# GPMC register map
Vendor: Texas Instruments
Peripheral module from a debugger description file (folder omap4430).
Registers are 32-bit, read-write, reset 0x0 unless marked. A register's access mark holds for its fields unless they carry their own. Offsets are as the file gives them; lines under a group give offsets from that group; [hi:lo] are bit positions; {n}, {i} and the like mark numbered series; 'fields as' and 'values as' point back to an identical list; <NAME> marks a mode.

## GPMC
0x00 GPMC_REVISION ro reset not defined — This register contains the IP revision code.
  [31:0] REVISION — IP revision
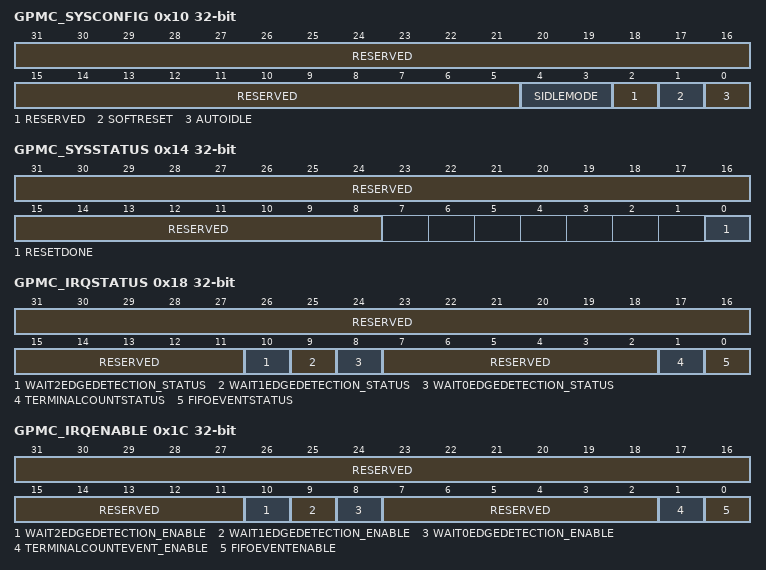
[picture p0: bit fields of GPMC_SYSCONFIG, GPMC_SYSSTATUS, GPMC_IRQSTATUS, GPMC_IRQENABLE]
0x10 GPMC_SYSCONFIG — This register controls the various parameters of the Interconnect.
  [31:5] RESERVED — Write 0s for future compatibility. Reads return 0s.
  [4:3] SIDLEMODE — 0x0: Force-idle. An idle request is acknowledged unconditionally
    1=No-idle. An idle request is never acknowledged; 2=Smart-idle. Acknowledgment to an idle request is given based on the internal activity of the module; 3=Do not use
  [2] RESERVED — Write 0 for future compatibility Reads returns 0
  [1] SOFTRESET — Software reset. Set this bit to 1 triggers a module reset. This bit is automatically reset by hardware. During reads, it always returns 0.
    0=Normal mode; 1=The module is reset
  [0] AUTOIDLE — Internal Interface clock gating strategy
    0=Interface clock is free-running; 1=Automatic Interface clock gating strategy is applied, based on the Interconnect activity
0x14 GPMC_SYSSTATUS ro (reset mask 0xFFFFFFFE) — This register provides status information about the module, excluding the interrupt status information
  [31:8] RESERVED — Reads returns 0
  [0] RESETDONE — Internal reset monitoring
    0=Internal module reset in ongoing; 1=Reset completed
0x18 GPMC_IRQSTATUS — This interrupt status register regroups all the status of the module internal events that can generate an interrupt.
  [31:11] RESERVED — Write 0s for future compatibility. Read returns 0s.
  [10] WAIT2EDGEDETECTION_STATUS — Status of the Wait2 Edge Detection interrupt
    0=WAIT2EDGEDETECTION_STATUS_0_r (A transition on WAIT2 input pin has not been detected); 0=WAIT2EDGEDETECTION_STATUS_0_w (WAIT2EDGEDETECTIONSTATUS bit unchanged); 1=WAIT2EDGEDETECTION_STATUS_1_r (A transition on WAIT2 input pin has been detected); 1=WAIT2EDGEDETECTION_STATUS_1_w (WAIT2EDGEDETECTIONSTATUS bit is reset)
  [9] WAIT1EDGEDETECTION_STATUS — Status of the Wait1 Edge Detection interrupt
    0=WAIT1EDGEDETECTION_STATUS_0_r (A transition on WAIT1 input pin has not been detected); 0=WAIT1EDGEDETECTION_STATUS_0_w (WAIT1EDGEDETECTIONSTATUS bit unchanged); 1=WAIT1EDGEDETECTION_STATUS_1_r (A transition on WAIT1 input pin has been detected); 1=WAIT1EDGEDETECTION_STATUS_1_w (WAIT1EDGEDETECTIONSTATUS bit is reset)
  [8] WAIT0EDGEDETECTION_STATUS — Status of the Wait0 Edge Detection interrupt
    0=WAIT0EDGEDETECTION_STATUS_0_r (A transition on WAIT0 input pin has not been detected); 0=WAIT0EDGEDETECTION_STATUS_0_w (WAIT0EDGEDETECTIONSTATUS bit unchanged); 1=WAIT0EDGEDETECTION_STATUS_1_r (A transition on WAIT0 input pin has been detected); 1=WAIT0EDGEDETECTION_STATUS_1_w (WAIT0EDGEDETECTIONSTATUS bit is reset)
  [7:2] RESERVED — Write 0s for future compatibility. Read returns 0s.
  [1] TERMINALCOUNTSTATUS — Status of the TerminalCountEvent interrupt
    0=TERMINALCOUNTSTATUS_0_r (Indicates that CountValue is greater than 0); 0=TERMINALCOUNTSTATUS_0_w (TERMINALCOUNTSTATUS bit unchanged); 1=TERMINALCOUNTSTATUS_1_r (Indicates that CountValue is equal to 0); 1=TERMINALCOUNTSTATUS_1_w (TERMINALCOUNTSTATUS bit is reset)
  [0] FIFOEVENTSTATUS — Status of the FIFOEvent interrupt
    0=FIFOEVENTSTATUS_0_r (Indicates than less than[16] FIFOTHRESHOLDSTATUS bytes are available in prefetch mode and less than FIFOTHRESHOLD bytes free places are available in write-posting mode.); 0=FIFOEVENTSTATUS_0_w (FIFOEVENTSTATUS bit unchanged); 1=FIFOEVENTSTATUS_1_r (Indicates than at least[16] FIFOTHRESHOLDSTATUS bytes are available in prefetch mode and at least FIFOTHRESHOLD bytes free places are available in write-posting mode.); 1=FIFOEVENTSTATUS_1_w (FIFOEVENTSTATUS bit is reset)
0x1C GPMC_IRQENABLE — The interrupt enable register allows to mask/unmask the module internal sources of interrupt, on a event-by-event basis.
  [31:11] RESERVED — Write 0s for future compatibility. Read returns 0s.
  [10] WAIT2EDGEDETECTION_ENABLE — Enables the Wait2 Edge Detection interrupt
    0=Wait2EdgeDetection interrupt is masked; 1=Wait2EdgeDetection event generates an interrupt if occurs
  [9] WAIT1EDGEDETECTION_ENABLE — Enables the Wait1 Edge Detection interrupt
    0=Wait1EdgeDetection interrupt is masked; 1=Wait1EdgeDetection event generates an interrupt if occurs
  [8] WAIT0EDGEDETECTION_ENABLE — Enables the Wait0 Edge Detection interrupt
    0=Wait0EdgeDetection interrupt is masked; 1=Wait0EdgeDetection event generates an interrupt if occurs
  [7:2] RESERVED — Write 0s for future compatibility. Read returns 0s.
  [1] TERMINALCOUNTEVENT_ENABLE — Enables TerminalCountEvent interrupt issuing in prefetch or write-posting mode
    0=TerminalCountEvent interrupt is masked; 1=TerminalCountEvent interrupt is not masked
  [0] FIFOEVENTENABLE — Enables the FIFOEvent interrupt
    0=FIFOEvent interrupt is masked; 1=FIFOEvent interrupt is not masked
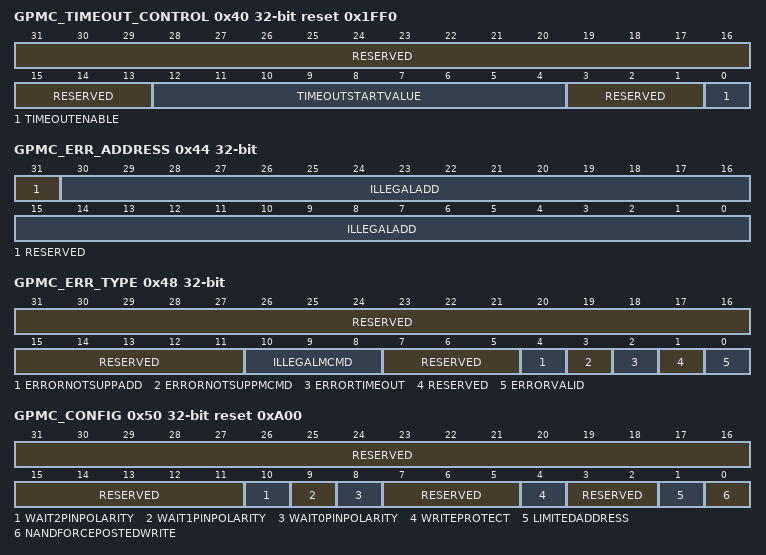
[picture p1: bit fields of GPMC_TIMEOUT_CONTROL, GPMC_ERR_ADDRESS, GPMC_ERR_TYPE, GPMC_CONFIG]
0x40 GPMC_TIMEOUT_CONTROL reset 0x1FF0 — The register allows the user to set the start value of the timeout counter
  [31:13] RESERVED — Write 0s for future compatibility. Read returns 0s.
  [12:4] TIMEOUTSTARTVALUE — Start value of the time-out counter 0x000: Zero GPMC_FCLK cycle 0x001: One GPMC_FCLK cycle ... 0x1FF: 511 GPMC_FCLK cycles
  [3:1] RESERVED — Write 0s for future compatibility. Read returns 0s.
  [0] TIMEOUTENABLE — Enable bit of the TimeOut feature
    0=TimeOut feature is disabled; 1=TimeOut feature is enabled
0x44 GPMC_ERR_ADDRESS access per field — The register stores the address of the illegal access when an error occurs
  [31] RESERVED rw — Write 0s for future compatibility. Read returns 0.
  [30:0] ILLEGALADD ro — Address of illegal access A30: 0 for memory region, 1 for GPMC register region A29-A0: 1 GBytes max
0x48 GPMC_ERR_TYPE access per field — The register stores the type of error when an error occurs
  [31:11] RESERVED rw — Write 0s for future compatibility. Read returns 0s.
  [10:8] ILLEGALMCMD ro — System Command of the transaction that caused the error
  [7:5] RESERVED rw — Write 0s for future compatibility. Read returns 0s.
  [4] ERRORNOTSUPPADD ro — Not supported Address error
    0=No error occurs; 1=The error is due to a non supported Address
  [3] ERRORNOTSUPPMCMD ro — Not supported Command error
    0=No error occurs; 1=The error is due to a non supported Command
  [2] ERRORTIMEOUT ro — Time-out error
    0=No error occurs; 1=The error is due to a time out
  [1] RESERVED rw — Write 0s for future compatibility. Read returns 0.
  [0] ERRORVALID rw — Error validity status - Must be explicitly cleared with a write 1 transaction
    0=All error fields no longer valid; 1=Error detected and logged in the other error fields
0x50 GPMC_CONFIG reset 0xA00 — The configuration register allows global configuration of the GPMC
  [31:11] RESERVED — Write 0s for future compatibility. Read returns 0s.
  [10] WAIT2PINPOLARITY — Selects the polarity of input pin WAIT2
    0=WAIT2 active low; 1=WAIT2 active high
  [9] WAIT1PINPOLARITY — Selects the polarity of input pin WAIT1
    0=WAIT1 active low; 1=WAIT1 active high
  [8] WAIT0PINPOLARITY — Selects the polarity of input pin WAIT0
    0=WAIT0 active low; 1=WAIT0 active high
  [7:5] RESERVED — Write 0s for future compatibility. Read returns 0s.
  [4] WRITEPROTECT — Controls the WP output pin level
    0=WP output pin is low; 1=WP output pin is high
  [3:2] RESERVED — Write 0s for future compatibility. Read returns 0s.
  [1] LIMITEDADDRESS — Limited Address device support
    0=No effect; 1=A26-A11 are not modified during an external memory access
  [0] NANDFORCEPOSTEDWRITE — Enables the Force Posted Write feature to NAND Cmd/Add/Data location
    0=Disables Force Posted Write; 1=Enables Force Posted Write
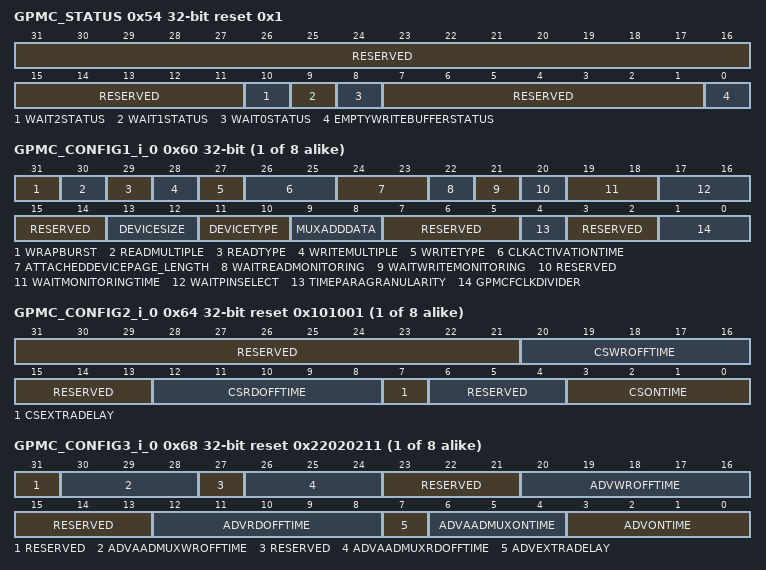
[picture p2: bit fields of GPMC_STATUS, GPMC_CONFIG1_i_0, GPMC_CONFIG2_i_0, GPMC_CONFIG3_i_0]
0x54 GPMC_STATUS access per field reset 0x1 (reset mask 0xFFFFF8FF) — The status register provides global status bits of the GPMC
  [31:11] RESERVED rw — Write 0s for future compatibility. Read returns 0s.
  [10] WAIT2STATUS ro — Is a copy of input pin WAIT2. (Reset value is WAIT2 input pin sampled at IC reset)
    0=WAIT2 asserted (inactive state); 1=WAIT2 deasserted
  [9] WAIT1STATUS ro — Is a copy of input pin WAIT1. (Reset value is WAIT1 input pin sampled at IC reset)
    0=WAIT1 asserted (inactive state); 1=WAIT1 deasserted
  [8] WAIT0STATUS ro — Is a copy of input pin WAIT0. (Reset value is WAIT0 input pin sampled at IC reset)
    0=WAIT0 asserted (inactive state); 1=WAIT0 deasserted
  [7:1] RESERVED rw — Write 0s for future compatibility. Reads returns 0
  [0] EMPTYWRITEBUFFERSTATUS ro — Stores the empty status of the write buffer
    0=Write Buffer is not empty; 1=Write Buffer is empty
{0x60+0x30*i} GPMC_CONFIG1_i_{i} (reset mask 0xFFBCCCFF) (i=0..7) — The configuration register 1 sets signal control parameters per chip-select
  [31] WRAPBURST — Enables the wrapping burst capability. Must be set if the attached device is configured in wrapping burst
    0=Synchronous wrapping burst not supported; 1=Synchronous wrapping burst supported
  [30] READMULTIPLE — Selects the read single or multiple access
    0=Single access; 1=Multiple access (burst if synchronous, page if asynchronous)
  [29] READTYPE — Selects the read mode operation
    0=Read Asynchronous; 1=Read Synchronous
  [28] WRITEMULTIPLE — Selects the write single or multiple access
    0=Single access; 1=Multiple access (burst if synchronous, considered as single if asynchronous)
  [27] WRITETYPE — Selects the write mode operation
    0=Write Asynchronous; 1=Write Synchronous
  [26:25] CLKACTIVATIONTIME — Output GPMC_CLK activation time
    0=First rising edge of GPMC_CLK at start access time; 1=First rising edge of GPMC_CLK one GPMC_FCLK cycle after start access time; 2=First rising edge of GPMC_CLK two GPMC_FCLK cycles after start access time
  [24:23] ATTACHEDDEVICEPAGE_LENGTH — Specifies the attached device page (burst) length
    0=4 Words; 1=8 Words; 2=16 Words
  [22] WAITREADMONITORING — Selects the Wait monitoring configuration for Read accesses (Reset value is input pin sampled at IC reset)
    0=Wait pin is not monitored for read accesses; 1=Wait pin is monitored for read accesses
  [21] WAITWRITEMONITORING — Selects the Wait monitoring configuration for Write accesses
    0=Wait pin is not monitored for write accesses; 1=Wait pin is monitored for write accesses
  [20] RESERVED — Write 0s for future compatibility. Read returns 0.
  [19:18] WAITMONITORINGTIME — Selects input pin Wait monitoring time
    0=Wait pin is monitored with valid data; 1=Wait pin is monitored one GPMC_CLK cycle before valid data; 2=Wait pin is monitored two GPMC_CLK cycle before valid data
  [17:16] WAITPINSELECT — Selects the input WAIT pin for this chip-select (Reset value is input pin sampled at IC reset for CS0 and 0 for CS1-7)
    0=Wait input pin is WAIT0; 1=Wait input pin is WAIT1; 2=Wait input pin is WAIT2
  [15:14] RESERVED — Write 0s for future compatibility. Reads returns 0
  [13:12] DEVICESIZE — Selects the device size attached (Reset value is input pin sampled at IC reset for CS0 and 0x1 for CS1 to CS7)
    0=8 bit; 1=16 bit
  [11:10] DEVICETYPE — Selects the attached device type
    0=NOR Flash like, asynchronous and synchronous devices; 2=NAND Flash like devices, stream mode
  [9:8] MUXADDDATA — Enables the address and data multiplexed protocol (Reset value is input pin sampled at IC reset for CS0 and 0 for CS1-CS7)
    0=Non-multiplexed attached device; 1=AAD-mux protocol device; 2=Address and data multiplexed attached device
  [7:5] RESERVED — Write 0s for future compatibility. Read returns 0s.
  [4] TIMEPARAGRANULARITY — Signals timing latencies scalar factor (RD/WRCYCLETIME, RD/WRACCESSTIME, PAGEBURSTACCESSTIME, CSONTIME, CSRD/WROFFTIME, ADVONTIME, ADVRD/WROFFTIME, OEONTIME, OEOFFTIME, WEONTIME, WEOFFTIME, CYCLE2CYCLEDELAY, BUSTURNAROUND, TIMEOUTSTARTVALUE, WRDATAONADMUXBUS)
    0=x1 latencies; 1=x2 latencies
  [3:2] RESERVED — Write 0s for future compatibility. Read returns 0s.
  [1:0] GPMCFCLKDIVIDER — Divides the GPMC_FCLK clock
    0=GPMC_CLK frequency = GPMC_FCLK frequency; 1=GPMC_CLK frequency = GPMC_FCLK frequency / 2; 2=GPMC_CLK frequency = GPMC_FCLK frequency / 3; 3=GPMC_CLK frequency = GPMC_FCLK frequency /4
{0x64+0x30*i} GPMC_CONFIG2_i_{i} reset 0x101001 (i=0..7) — CS signal timing parameter configuration
  [31:21] RESERVED — Write 0s for future compatibility. Reads returns 0
  [20:16] CSWROFFTIME — CS i de-assertion time from start cycle time for write accesses 0x00: 0 GPMC_FCLK cycle 0x01: 1 GPMC_FCLK cycle ... 0x1F: 31 GPMC_FCLK cycles
  [15:13] RESERVED — Write 0s for future compatibility. Read returns 0s.
  [12:8] CSRDOFFTIME — CS i de-assertion time from start cycle time for read accesses 0x00: 0 GPMC_FCLK cycle 0x01: 1 GPMC_FCLK cycle ... 0x1F: 31 GPMC_FCLK cycles
  [7] CSEXTRADELAY — CS i Add Extra Half GPMC_FCLK cycle
    0=CS i Timing control signal is not delayed; 1=CS i Timing control signal is delayed of half GPMC_FCLK clock cycle
  [6:4] RESERVED — Write 0s for future compatibility. Read returns 0s.
  [3:0] CSONTIME — CS i assertion time from start cycle time 0x0: 0 GPMC_FCLK cycle 0x1: 1 GPMC_FCLK cycle ... 0xF: 15 GPMC_FCLK cycles
{0x68+0x30*i} GPMC_CONFIG3_i_{i} reset 0x22020211 (i=0..7) — nADV signal timing parameter configuration
  [31] RESERVED — Write 0s for future compatibility. Read returns 0s.
  [30:28] ADVAADMUXWROFFTIME — nADV de-assertion for first address phase when using the AAD-mux protocol 0x0: 0 GPMC_FCLK cycle 0x1: 1 GPMC_FCLK cycle ... 0x7: 7 GPMC_FCLK cycles
  [27] RESERVED — Write 0s for future compatibility. Read returns 0s.
  [26:24] ADVAADMUXRDOFFTIME — nADV assertion for first address phase when using the AAD-mux protocol 0x0: 0 GPMC_FCLK cycle 0x1: 1 GPMC_FCLK cycle ... 0x7: 7 GPMC_FCLK cycles
  [23:21] RESERVED — Write 0s for future compatibility. Read returns 0s.
  [20:16] ADVWROFFTIME — nADV de-assertion time from start cycle time for write accesses 0x00: 0 GPMC_FCLK cycle 0x01: 1 GPMC_FCLK cycle ... 0x1F: 31 GPMC_FCLK cycles
  [15:13] RESERVED — Write 0s for future compatibility. Read returns 0s.
  [12:8] ADVRDOFFTIME — nADV de-assertion time from start cycle time for read accesses 0x00: 0 GPMC_FCLK cycle 0x01: 1 GPMC_FCLK cycle ... 0x1F: 31 GPMC_FCLK cycles
  [7] ADVEXTRADELAY — nADV Add Extra Half GPMC_FCLK cycle
    0=nADV Timing control signal is not delayed; 1=nADV Timing control signal is delayed of half GPMC_FCLK clock cycle
  [6:4] ADVAADMUXONTIME — nADV assertion for first address phase when using the AAD-mux protocol 0x0: 0 GPMC_FCLK cycle 0x1: 1 GPMC_FCLK cycle ... 0x7: 7 GPMC_FCLK cycles
  [3:0] ADVONTIME — nADV assertion time from start cycle time 0x0: 0 GPMC_FCLK cycle 0x1: 1 GPMC_FCLK cycle ... 0xF: 15 GPMC_FCLK cycles
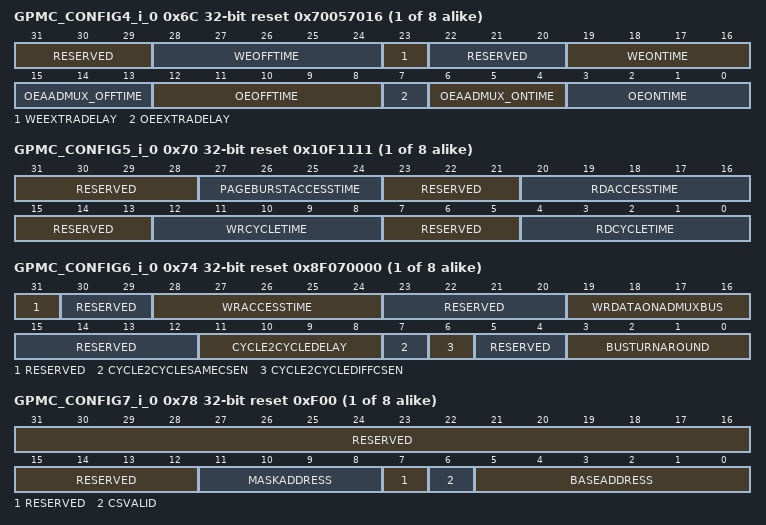
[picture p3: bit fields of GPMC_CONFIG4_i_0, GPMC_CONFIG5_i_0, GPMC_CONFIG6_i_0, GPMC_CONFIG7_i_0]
{0x6C+0x30*i} GPMC_CONFIG4_i_{i} reset 0x70057016 (i=0..7) — nWE and nOE signals timing parameter configuration
  [31:29] RESERVED — Write 0s for future compatibility. Read returns 0s.
  [28:24] WEOFFTIME — nWE de-assertion time from start cycle time 0x00: 0 GPMC_FCLK cycle 0x01: 1 GPMC_FCLK cycle ... 0x1F: 31 GPMC_FCLK cycles
  [23] WEEXTRADELAY — nWE Add Extra Half GPMC_FCLK cycle
    0=nWE Timing control signal is not delayed; 1=nWE Timing control signal is delayed of half GPMC_FCLK clock cycle
  [22:20] RESERVED — Write 0s for future compatibility. Read returns 0s.
  [19:16] WEONTIME — nWE assertion time from start cycle time 0x0: 0 GPMC_FCLK cycle 0x1: 1 GPMC_FCLK cycle ... 0xF: 15 GPMC_FCLK cycles
  [15:13] OEAADMUX_OFFTIME — nOE de-assertion time for the first address phase in an AAD-mux access 0x0: 0 GPMC_FCLK cycle 0x1: 1 GPMC_FCLK cycle ... 0x7: 7 GPMC_FCLK cycles
  [12:8] OEOFFTIME — nOE de-assertion time from start cycle time 0x00: 0 GPMC_FCLK cycle 0x01: 1 GPMC_FCLK cycle ... 0x1F: 31 GPMC_FCLK cycles
  [7] OEEXTRADELAY — nOE Add Extra Half GPMC_FCLK cycle
    0=nOE Timing control signal is not delayed; 1=nOE Timing control signal is delayed of half GPMC_FCLK clock cycle
  [6:4] OEAADMUX_ONTIME — nOE assertion time for the first address phase in an AAD-mux access 0x0: 0 GPMC_FCLK cycle 0x1: 1 GPMC_FCLK cycle ... 0x7: 7 GPMC_FCLK cycles
  [3:0] OEONTIME — nOE assertion time from start cycle time 0x0: 0 GPMC_FCLK cycle 0x1: 1 GPMC_FCLK cycle ... 0xF: 15 GPMC_FCLK cycles
{0x70+0x30*i} GPMC_CONFIG5_i_{i} reset 0x10F1111 (i=0..7) — RdAccessTime and CycleTime timing parameters configuration
  [31:28] RESERVED — Write 0s for future compatibility. Read returns 0s.
  [27:24] PAGEBURSTACCESSTIME — Delay between successive words in a multiple access 0x0: 0 GPMC_FCLK cycle 0x1: 1 GPMC_FCLK cycle ... 0xF: 15 GPMC_FCLK cycles
  [23:21] RESERVED — Write 0s for future compatibility. Read returns 0s.
  [20:16] RDACCESSTIME — Delay between start cycle time and first data valid 0x00: 0 GPMC_FCLK cycle 0x01: 1 GPMC_FCLK cycle ... 0x1F: 31 GPMC_FCLK cycles
  [15:13] RESERVED — Write 0s for future compatibility. Reads returns 0
  [12:8] WRCYCLETIME — Total write cycle time 0x00: 0 GPMC_FCLK cycle 0x01: 1 GPMC_FCLK cycle ... 0x1F: 31 GPMC_FCLK cycles
  [7:5] RESERVED — Write 0s for future compatibility. Read returns 0s.
  [4:0] RDCYCLETIME — Total read cycle time 0x00: 0 GPMC_FCLK cycle 0x01: 1 GPMC_FCLK cycle ... 0x1F: 31 GPMC_FCLK cycles
{0x74+0x30*i} GPMC_CONFIG6_i_{i} reset 0x8F070000 (i=0..7) — WrAccessTime, WrDataOnADmuxBus, Cycle2Cycle and BusTurnAround parameters configuration
  [31] RESERVED — TI Internal use - Do not modify.
  [30:29] RESERVED — Write 0s for future compatibility. Read returns 0s.
  [28:24] WRACCESSTIME — Delay from start access time to the GPMC_FCLK rising edge corresponding the the GPMC_CLK rising edge used by the attached memory for the first data capture 0x00: 0 GPMC_FCLK cycle 0x01: 1 GPMC_FCLK cycle ... 0x1F: 31 GPMC_FCLK cycles
  [23:20] RESERVED — Write 0s for future compatibility. Read returns 0s.
  [19:16] WRDATAONADMUXBUS — Specifies on which GPMC_FCLK rising edge the first data of the synchronous burst write is driven in the add/data mux bus
  [15:12] RESERVED — Write 0s for future compatibility. Read returns 0s.
  [11:8] CYCLE2CYCLEDELAY — Chip-select high pulse delay between successive accesses 0x0: 0 GPMC_FCLK cycle 0x1: 1 GPMC_FCLK cycle ... 0xF: 15 GPMC_FCLK cycles
  [7] CYCLE2CYCLESAMECSEN — Add CYCLE2CYCLEDELAY between successive accesses to the same CS (any access type)
    0=No delay between the two accesses; 1=Add CYCLE2CYCLEDELAY
  [6] CYCLE2CYCLEDIFFCSEN — Add CYCLE2CYCLEDELAY between successive accesses to a different CS (any access type)
    0=No delay between the two accesses; 1=Add CYCLE2CYCLEDELAY
  [5:4] RESERVED — Write 0s for future compatibility. Reads returns 0
  [3:0] BUSTURNAROUND — Bus turn around latency between successive accesses to the same CS (read to write) or to a different CS (read to read and read to write) 0x0: 0 GPMC_FCLK cycle 0x1: 1 GPMC_FCLK cycle ... 0xF: 15 GPMC_FCLK cycles
{0x78+0x30*i} GPMC_CONFIG7_i_{i} reset 0xF00 (reset mask 0xFFFFFFBF) (i=0..7) — CS address mapping configuration
  [31:12] RESERVED — Write 0s for future compatibility. Read returns 0s.
  [11:8] MASKADDRESS — CS mask address. 0x1000: Chip-select size of 128 Mbytes 0x1100: Chip-select size of 64 Mbytes 0x1110: Chip-select size of 32 Mbytes 0x1111: Chip-select size of 16 Mbytes Other values must be avoided as they create holes in the chip-select address space.
  [7] RESERVED — Write 0s for future compatibility. Read returns 0.
  [6] CSVALID — CS enable
    0=CS disabled; 1=CS enabled
  [5:0] BASEADDRESS — CSi base address where i = 0 to 7 (16M bytes minimum granularity) bits [5:0] corresponds to A29, A28, A27, A26, A25, and A24. See
{0x7C+0x30*i} GPMC_NAND_COMMAND_i_{i} wo reset not defined (i=0..7) — This register is not a true register, just an address location.
  [31:0] GPMC_NAND_COMMAND — This register is not a true register, just an address location. Writing data at theGPMC_NAND_COMMAND_i location places the data as the NAND command value on the bus, using a regular asynchronous write access.
{0x80+0x30*i} GPMC_NAND_ADDRESS_i_{i} wo reset not defined (i=0..7) — This register is not a true register, just an address location.
  [31:0] GPMC_NAND_ADDRESS — This register is not a true register, just an address location. Writing data at theGPMC_NAND_ADDRESS_i location places the data as the NAND partial address value on the bus, using a regular asynchronous write access.
{0x84+0x30*i} GPMC_NAND_DATA_i_{i} wo reset not defined (i=0..7) — This register is not a true register, just an address location.
  [31:0] GPMC_NAND_DATA — This register is not a true register, just an address location. Reading data from theGPMC_NAND_DATA_i location or from any location in the associated chip-select memory region activates an asynchronous read access.
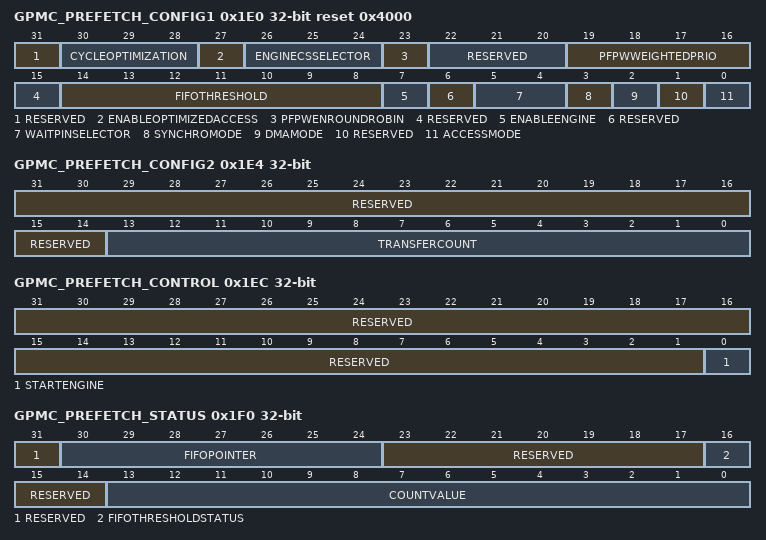
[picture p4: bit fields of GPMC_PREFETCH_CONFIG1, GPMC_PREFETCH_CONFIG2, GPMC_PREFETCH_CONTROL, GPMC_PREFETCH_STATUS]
0x1E0 GPMC_PREFETCH_CONFIG1 reset 0x4000 — Prefetch engine configuration 1
  [31] RESERVED — Write 0s for future compatibility. Read returns 0.
  [30:28] CYCLEOPTIMIZATION — Define the number of GPMC_FCLK cycles to be subtracted from RDCYCLETIME, WRCYCLETIME, ACCESSTIME, CSRDOFFTIME, CSWROFFTIME, ADVRDOFFTIME, ADVWROFFTIME, OEOFFTIME, WEOFFTIME 0x0: 0 GPMC_FCLK cycle 0x1: 1 GPMC_FCLK cycle ... 0x7: 7 GPMC_FCLK cycles
  [27] ENABLEOPTIMIZEDACCESS — Enables access cycle optimization
    0=Access cycle optimization is disabled; 1=Access cycle optimization is enabled
  [26:24] ENGINECSSELECTOR — Selects the CS where Prefetch Postwrite engine is active 0x0: CS0 0x1: CS1 0x2: CS2 0x3: CS3 0x4: CS4 0x5: CS5 0x6: CS6 0x7: CS7
  [23] PFPWENROUNDROBIN — Enables the PFPW RoundRobin arbitration
    0=Prefetch Postwrite engine round robin arbitration is disabled; 1=Prefetch Postwrite engine round robin arbitration is enabled
  [22:20] RESERVED — Write 0s for future compatibility. Read returns 0s.
  [19:16] PFPWWEIGHTEDPRIO — When an arbitration occurs between a DMA and a PFPW engine access, the DMA is always serviced. If the PFPWEnRoundRobin is enabled, 0x0: the next access is granted to the PFPW engine, 0x1: the two next accesses are granted to the PFPW engine, ..., 0xF: the 16 next accesses are granted to the PFPW engine.
  [15] RESERVED — Write 0s for future compatibility. Read returns 0.
  [14:8] FIFOTHRESHOLD — Selects the maximum number of bytes read from the FIFO or written to the FIFO by the host on a DMA or interrupt request 0x00: 0 byte 0x01: 1 byte ... 0x40: 64 bytes
  [7] ENABLEENGINE — Enables the Prefetch Postwite engine
    0=Prefetch Postwrite engine is disabled; 1=Prefetch Postwrite engine is enabled
  [6] RESERVED — Write 0s for future compatibility. Read returns 0.
  [5:4] WAITPINSELECTOR — Select which wait pin edge detector should start the engine in synchronized mode
    0=Selects Wait0 EdgeDetection; 1=Selects Wait1 EdgeDetection; 2=Selects Wait2 EdgeDetection
  [3] SYNCHROMODE — Selects when the engine starts the access to CS
    0=Engine starts the access to CS as soon as STARTENGINE is set; 1=Engine starts the access to CS as soon as STARTENGINE is set AND wait to non wait edge detection on the selected wait pin
  [2] DMAMODE — Selects interrupt synchronization or DMA request synchronization
    0=Interrupt synchronization is enabled. Only interrupt line will be activated on FIFO threshold crossing.; 1=DMA request synchronization is enabled. A DMA request protocol is used.
  [1] RESERVED — Write 0s for future compatibility. Read returns 0.
  [0] ACCESSMODE — Selects prefetch read or write-posting accesses
    0=Prefetch read mode; 1=Write-posting mode
0x1E4 GPMC_PREFETCH_CONFIG2 — Prefetch engine configuration 2
  [31:14] RESERVED — Write 0s for future compatibility. Read returns 0s.
  [13:0] TRANSFERCOUNT — Selects the number of bytes to be read or written by the engine to the selected CS 0x0000: 0 byte 0x0001: 1 byte ... 0x2000: 8 Kbytes
0x1EC GPMC_PREFETCH_CONTROL — Prefetch engine control
  [31:1] RESERVED — Write 0s for future compatibility. Read returns 0s.
  [0] STARTENGINE — Resets the FIFO pointer and starts the engineWrite 0x0 stops the engine . Write 0x1 resets the FIFO pointer to 0x0 in prefetch mode and 0x40 in postwrite mode and starts the engine .
    0=STARTENGINE_0_r (Engine is stopped); 1=STARTENGINE_1_r (Engine is running)
0x1F0 GPMC_PREFETCH_STATUS access per field — Prefetch engine status
  [31] RESERVED rw — Write 0s for future compatibility. Read returns 0.
  [30:24] FIFOPOINTER ro — Number of available bytes to be read or number of free empty byte places to be written 0x00: 0 byte available to be read or 0 free empty place to be written ... 0x40: 64 bytes available to be read or 64 empty places to be written
  [23:17] RESERVED rw — Write 0s for future compatibility. Read returns 0s.
  [16] FIFOTHRESHOLDSTATUS ro — Set when FIFOPointer exceeds FIFOThreshold value
    0=FIFOPointer smaller or equal to FIFOThreshold. Writing to this bit has no effect; 1=FIFOPointer greater than FIFOThreshold. Writing to this bit has no effect
  [15:14] RESERVED rw — Write 0s for future compatibility. Read returns 0s.
  [13:0] COUNTVALUE ro — Number of remaining bytes to be read or to be written by the engine according to the TransferCount value 0x0000: 0 byte remaining to be read or to be written 0x0001: 1 byte remaining to be read or to be written ... 0x2000: 8 Kbytes remaining to be read or to be written
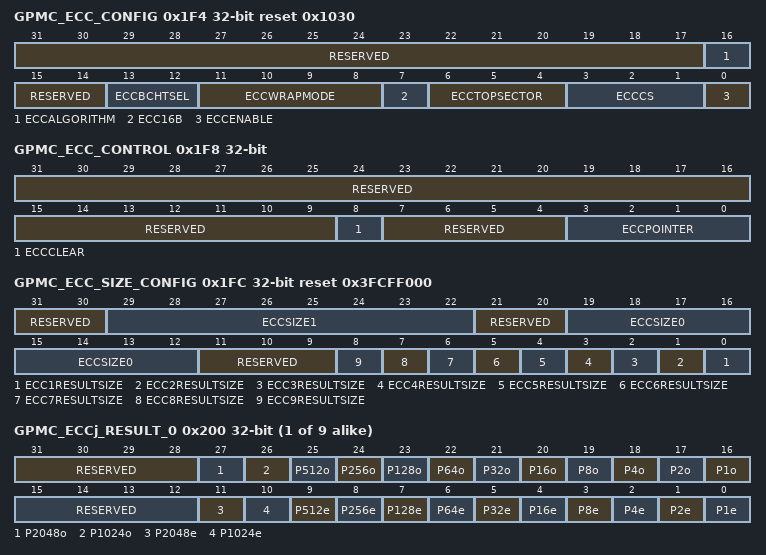
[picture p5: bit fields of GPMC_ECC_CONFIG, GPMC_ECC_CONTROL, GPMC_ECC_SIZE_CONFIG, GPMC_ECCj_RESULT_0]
0x1F4 GPMC_ECC_CONFIG reset 0x1030 — ECC configuration
  [31:17] RESERVED — Write 0s for future compatibility. Read returns 0s.
  [16] ECCALGORITHM — ECC algorithm used
    0=Hamming code; 1=BCH code
  [15:14] RESERVED — Write 0s for future compatibility. Read returns 0s.
  [13:12] ECCBCHTSEL — Error correction capability used for BCH
    0=Up to 4 bits error correction (t = 4); 1=Up to 8 bits error correction (t = 8); 2=Up to 16 bits error correction (t = 16)
  [11:8] ECCWRAPMODE — Spare area organization definition for the BCH algorithm. See the BCH syndrome/parity calculator module functional specification for more details
  [7] ECC16B — Selects an ECC calculated on 16 columns
    0=ECC calculated on 8 columns; 1=ECC calculated on 16 columns
  [6:4] ECCTOPSECTOR — Number of sectors to process with the BCH algorithm 0x0: 1 sector (512kB page) 0x1: 2 sectors ... 0x3: 4 sectors (2kB page) ... 0x7: 8 sectors (4kB page)
  [3:1] ECCCS — Selects the CS where ECC is computedOther: Reserved .
    {v}=Chip-select {v} (v=0..3)
  [0] ECCENABLE — Enables the ECC feature
    0=ECC disabled; 1=ECC enabled
0x1F8 GPMC_ECC_CONTROL — ECC control
  [31:9] RESERVED — Write 0s for future compatibility. Read returns 0s.
  [8] ECCCLEAR — Clear all ECC result registers Reads returns 0 Write 0x1 to this field clear all ECC result registers Write 0x0 is ignored
  [7:4] RESERVED — Write 0s for future compatibility. Read returns 0s.
  [3:0] ECCPOINTER — Selects ECC result register (Reads to this field give the dynamic position of the ECC pointer - Writes to this field select the ECC result register where the first ECC computation will be stored); Other enums: writing other values disables the ECC engine (ECCENABLE bit ofGPMC_ECC_CONFIG set to 0)
    0=Writing 0x0 disables the ECC engine (ECCENABLE bit of set to 0); {v}=ECC result register {v} selected (v=1..9)
0x1FC GPMC_ECC_SIZE_CONFIG reset 0x3FCFF000 — ECC size
  [31:30] RESERVED — Write 0s for future compatibility. Read returns 0s.
  [29:22] ECCSIZE1 — Defines Hamming code ECC size 1 in bytes 0x00: 2 Bytes 0x01: 4 Bytes 0x02: 6 Bytes 0x03: 8 Bytes ... 0xFF: 512 Bytes For BCH code ECC, the size 1 is programmed directly with the number of nibbles (see , ).
  [21:20] RESERVED — Write 0s for future compatibility. Read returns 0s.
  [19:12] ECCSIZE0 — Defines Hamming code ECC size 0 in bytes 0x00: 2 Bytes 0x01: 4 Bytes 0x02: 6 Bytes 0x03: 8 Bytes ... 0xFF: 512 Bytes For BCH code ECC, the size 0 is programmed directly with the number of nibbles (see , ).
  [11:9] RESERVED — Write 0s for future compatibility. Read returns 0s.
  [n-1] ECC{n}RESULTSIZE (n=1..9) — Selects ECC size for ECC {n} result register
    0=ECCSIZE0 selected; 1=ECCSIZE1 selected
{0x200+4i} GPMC_ECCj_RESULT_{i} access per field (i=0..8) — ECC result register
  [31:28] RESERVED rw — Write 0s for future compatibility. Read returns 0s.
  [27] P2048o ro — Odd row parity bit 2048, only used for ECC computed on 512 Bytes
  [26] P1024o ro — Odd row parity bit 1024
  [25] P512o ro — Odd row parity bit 512
  [24] P256o ro — Odd row parity bit 256
  [23] P128o ro — Odd row parity bit 128
  [22] P64o ro — Odd row parity bit 64
  [21] P32o ro — Odd row parity bit 32
  [20] P16o ro — Odd row parity bit 16
  [19] P8o ro — Odd row parity bit 8
  [18] P4o ro — Odd Column Parity bit 4
  [17] P2o ro — Odd Column Parity bit 2
  [16] P1o ro — Odd Column Parity bit 1
  [15:12] RESERVED rw — Write 0s for future compatibility. Read returns 0s.
  [11] P2048e ro — Even row parity bit 2048, only used for ECC computed on 512 Bytes
  [10] P1024e ro — Even row parity bit 1024
  [9] P512e ro — Even row parity bit 512
  [8] P256e ro — Even row parity bit 256
  [7] P128e ro — Even row parity bit 128
  [6] P64e ro — Even row parity bit 64
  [5] P32e ro — Even row parity bit 32
  [4] P16e ro — Even row parity bit 16
  [3] P8e ro — Even row parity bit 8
  [2] P4e ro — Even column parity bit 4
  [1] P2e ro — Even column parity bit 2
  [0] P1e ro — Even column parity bit 1
{0x240+0x10*i} GPMC_BCH_RESULT0_i_{i} (i=0..7) — BCH ECC result (bits 0 to 31)
  [31:0] BCH_RESULT_0
{0x244+0x10*i} GPMC_BCH_RESULT1_i_{i} (i=0..7) — BCH ECC result (bits 32 to 63)
  [31:0] BCH_RESULT_1
{0x248+0x10*i} GPMC_BCH_RESULT2_i_{i} (i=0..7) — BCH ECC result (bits 64 to 95)
  [31:0] BCH_RESULT_2
{0x24C+0x10*i} GPMC_BCH_RESULT3_i_{i} (i=0..7) — BCH ECC result (bits 96 to 127)
  [31:0] BCH_RESULT_3
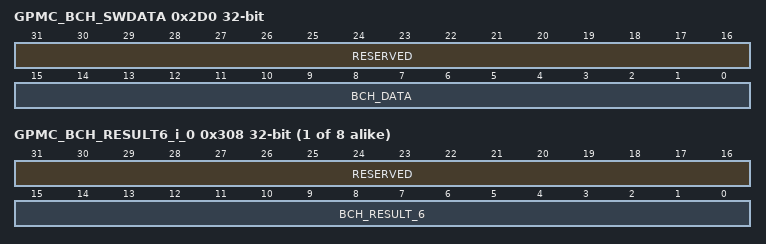
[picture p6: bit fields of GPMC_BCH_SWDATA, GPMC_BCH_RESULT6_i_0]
0x2D0 GPMC_BCH_SWDATA access per field — This register is used to directly pass data to the BCH ECC calculator without accessing the actual NAND flash interface.
  [31:16] RESERVED ro — Write 0s for future compatibility. Read returns 0s.
  [15:0] BCH_DATA rw — Data to be included in the BCH calculation. Only bits 0 to 7 are taken into account if the calculator is configured to use 8 bits data (GPMC_ECC_CONFIG[7] ECC16B = 0)
{0x300+0x10*i} GPMC_BCH_RESULT4_i_{i} (i=0..7) — BCH ECC result (bits 128 to 159)
  [31:0] BCH_RESULT_4
{0x304+0x10*i} GPMC_BCH_RESULT5_i_{i} (i=0..7) — BCH ECC result (bits 160 to 191)
  [31:0] BCH_RESULT_5
{0x308+0x10*i} GPMC_BCH_RESULT6_i_{i} access per field (i=0..7) — BCH ECC result (bits 192 to 207)
  [31:16] RESERVED ro — Write 0s for future compatibility. Read returns 0s.
  [15:0] BCH_RESULT_6 rw — BCH ECC result (bits 192 to 207)
